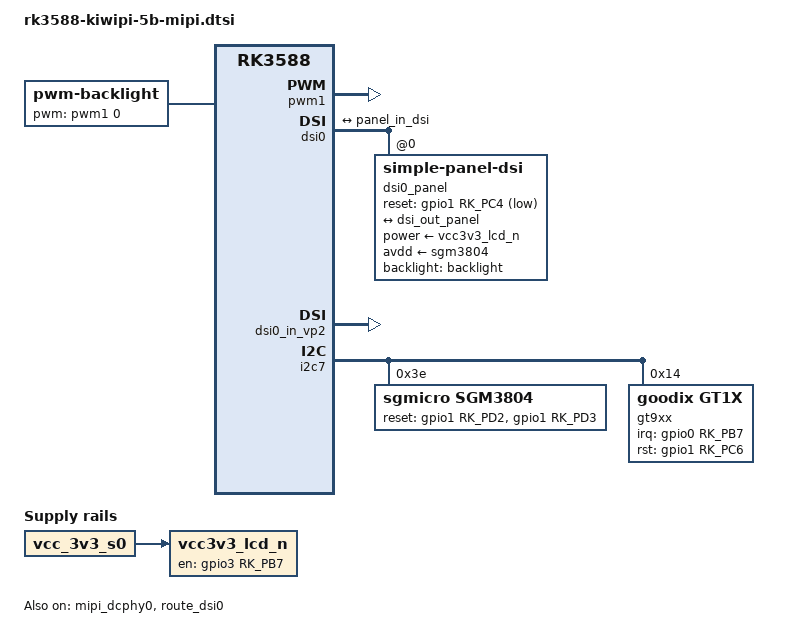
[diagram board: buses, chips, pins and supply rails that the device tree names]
// SPDX-License-Identifier: (GPL-2.0+ OR MIT)
/*
 * Copyright (c) 2021 Rockchip Electronics Co., Ltd.
 *
 */

/ {
	backlight: backlight {
		compatible = "pwm-backlight";
		pwms = <&pwm1 0 25000 0>;
		brightness-levels = <
			  0  20  20  21  21  22  22  23
			 23  24  24  25  25  26  26  27
			 27  28  28  29  29  30  30  31
			 31  32  32  33  33  34  34  35
			 35  36  36  37  37  38  38  39
			 40  41  42  43  44  45  46  47
			 48  49  50  51  52  53  54  55
			 56  57  58  59  60  61  62  63
			 64  65  66  67  68  69  70  71
			 72  73  74  75  76  77  78  79
			 80  81  82  83  84  85  86  87
			 88  89  90  91  92  93  94  95
			 96  97  98  99 100 101 102 103
			104 105 106 107 108 109 110 111
			112 113 114 115 116 117 118 119
			120 121 122 123 124 125 126 127
			128 129 130 131 132 133 134 135
			136 137 138 139 140 141 142 143
			144 145 146 147 148 149 150 151
			152 153 154 155 156 157 158 159
			160 161 162 163 164 165 166 167
			168 169 170 171 172 173 174 175
			176 177 178 179 180 181 182 183
			184 185 186 187 188 189 190 191
			192 193 194 195 196 197 198 199
			200 201 202 203 204 205 206 207
			208 209 210 211 212 213 214 215
			216 217 218 219 220 221 222 223
			224 225 226 227 228 229 230 231
			232 233 234 235 236 237 238 239
			240 241 242 243 244 245 246 247
			248 249 250 251 252 253 254 255
		>;
		default-brightness-level = <200>;
	};

	vcc3v3_lcd_n: vcc3v3-lcd0-n {
		compatible = "regulator-fixed";
		regulator-name = "vcc3v3_lcd0_n";
		enable-active-high;
		regulator-boot-on;
		gpio = <&gpio3 RK_PB7 GPIO_ACTIVE_HIGH>;
		vin-supply = <&vcc_3v3_s0>;
	};
};

&pwm1 {
	status = "okay";
};

&dsi0 {
	status = "okay";

	dsi0_panel: panel@0 {
		status = "okay";
		compatible = "simple-panel-dsi";
		reg = <0>;
		backlight = <&backlight>;
		power-supply = <&vcc3v3_lcd_n>;
		avdd-supply = <&sgm3804>;
		reset-gpios = <&gpio1 RK_PC4 GPIO_ACTIVE_LOW>;
		pinctrl-names = "default";
		pinctrl-0 = <&lcd_rst_gpio>;
		reset-delay-ms = <60>;
		enable-delay-ms = <200>;
		prepare-delay-ms = <60>;
		unprepare-delay-ms = <60>;
		disable-delay-ms = <60>;
		init-delay-ms = <60>;
		width-mm = <68>;
		height-mm = <121>;
		dsi,flags = <(MIPI_DSI_MODE_VIDEO | MIPI_DSI_MODE_VIDEO_BURST |
			MIPI_DSI_MODE_LPM | MIPI_DSI_MODE_EOT_PACKET)>;
		dsi,format = <MIPI_DSI_FMT_RGB888>;
		dsi,lanes  = <4>;
		panel-init-sequence = [
			39 00 04 B9 FF 83 99
			23 00 02 BA 43
			23 00 02 D2 44
			39 00 0D B1 00 7C 34 34 40 11 22 22 72 FA 76 58
			39 00 0B B2 00 80 00 7F 05 07 23 4D 21 01
			39 00 29 B4 00 FF 02 40 02 40 00 00 06 00 01 02 00 0F 01 02 05 20 00 04 44 02 40 02 40 00 00 06 00 01 02 00 0F 01 02 05 00 00 04 44
			39 00 20 D3 00 01 00 00 00 06 00 00 10 04 00 04 00 00 00 00 00 00 00 00 00 00 01 05 05 07 00 00 00 05 08
			39 00 21 D5 18 18 19 19 18 18 21 20 01 00 07 06 05 04 03 02 18 18 18 18 18 18 30 30 31 31 32 32 18 18 18 18
			39 00 21 D6 18 18 19 19 40 40 20 21 06 07 00 01 02 03 04 05 40 40 40 40 40 40 30 30 31 31 32 32 40 40 40 40
			39 00 31 D8 A2 AA 02 A0 A2 A8 02 A0 B0 00 00 00 B0 00 00 00 B0 00 00 00 B0 00 00 00 E2 AA 03 F0 E2 AA  03 F0 00 00 00 00 00 00 00 00 E2 AA 03 F0 E2 AA 03 F0
			39 00 03 B6 23 23
			39 00 2B E0 01 06 06 2A 2F 3E 0F 3A 05 09 0F 13 15 14 15 12 18 07 16 07 14 01 06 06 2A 2F 3E 0F 3A 05 09 0F 13 15 14 15 12 18 07 16 07 14
			39 00 04 C0 0E 91 00
			23 00 02 CC 08
			05 78 01 11
			05 14 01 29
		];

		panel-exit-sequence = [
			05 00 01 28
			05 00 01 10
		];

		disp_timings1: display-timings {
			native-mode = <&dsi0_timing0>;
			dsi0_timing0: timing0 {
				clock-frequency = <134000000>;
				hactive = <1080>;
				vactive = <1920>;
				hfront-porch = <20>;
				hsync-len = <28>;
				hback-porch = <28>;
				vfront-porch = <4>;
				vsync-len = <2>;
				vback-porch = <4>;
				hsync-active = <0>;
				vsync-active = <0>;
				de-active = <0>;
				pixelclk-active = <0>;
			};
		};

		ports {
			#address-cells = <1>;
			#size-cells = <0>;

			port@0 {
				reg = <0>;
				panel_in_dsi: endpoint {
					remote-endpoint = <&dsi_out_panel>;
				};
			};
		};
	};

	ports {
		#address-cells = <1>;
		#size-cells = <0>;

		port@1 {
			reg = <1>;
			dsi_out_panel: endpoint {
				remote-endpoint = <&panel_in_dsi>;
			};
		};
	};

};

&mipi_dcphy0 {
	status = "okay";
};

&dsi0_in_vp2 {
	status = "okay";
};

&route_dsi0 {
	status = "okay";
	connect = <&vp2_out_dsi0>;
};

&i2c7 {
	status = "okay";

	sgm3804: regulator@3e {
		compatible = "sgmicro,sgm3804";
		reg = <0x3e>;
		pinctrl-names = "default";
		pinctrl-0 = <&panel_pwr_active>;
		regulator-name = "panel-avdd";
		regulator-min-microvolt = <5000000>;
		regulator-max-microvolt = <5000000>;
        reset-gpios = <&gpio1 RK_PD2 GPIO_ACTIVE_HIGH>,
                      <&gpio1 RK_PD3 GPIO_ACTIVE_HIGH>;
	};
	
    gt9xx: gt9xx@14 {
		status = "okay";
        compatible = "goodix,gt1x";
        reg = <0x14>;
        pinctrl-names = "default";
        pinctrl-0 = <&gt9xx_gpio>;
		interrupt-parent = <&gpio0>;
		interrupts = <RK_PB7 IRQ_TYPE_EDGE_FALLING>;
        goodix,irq-gpio = <&gpio0 RK_PB7 IRQ_TYPE_EDGE_FALLING>;
        goodix,rst-gpio = <&gpio1 RK_PC6 GPIO_ACTIVE_HIGH>;
    };
};

&pinctrl {
	lcd {
		lcd_rst_gpio: lcd-rst-gpio {
			rockchip,pins = <1 RK_PC4 RK_FUNC_GPIO &pcfg_pull_up>;
		};
	};

    sgm3804 {
        panel_pwr_active: panel-pwr-active{
            rockchip,pins = <1 RK_PD2 RK_FUNC_GPIO &pcfg_pull_none>,
							<1 RK_PD3 RK_FUNC_GPIO &pcfg_pull_none>;					
        };
    };

    gt9xx {
        gt9xx_gpio: gt9xx-gpio {
            rockchip,pins = <0 RK_PB7 RK_FUNC_GPIO &pcfg_pull_up>,
							<1 RK_PC6 RK_FUNC_GPIO &pcfg_pull_none>;					
        };
    };
};
